# A64 register map
Vendor: Allwinner; Series: A64; File version: 0.1
CPU: CA53 0, little endian, MPU, no FPU, 0 interrupt priority bits
Registers are 32-bit, read-write, reset 0x0 unless marked. A register's access mark holds for its fields unless they carry their own. Offsets are from the block's base; [hi:lo] are bit positions; 'fields as' and 'values as' point back to an identical list; <NAME> marks a mode.

## AC (part 2 of 2)
Base 0x01C22C00
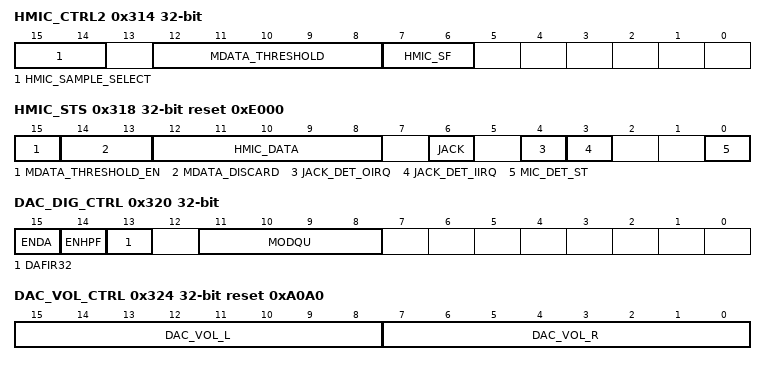
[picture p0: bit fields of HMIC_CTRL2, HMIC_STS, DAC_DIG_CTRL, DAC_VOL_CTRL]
0x314 HMIC_CTRL2 — HMIC Control 2 Register
  [15:14] HMIC_SAMPLE_SELECT — Down Sample Setting Select 00 : Down by 1, 128Hz 01 : Down by 2, 64Hz 10 : Down by 4, 32Hz 11 : Down by 8, 16Hz
  [12:8] MDATA_THRESHOLD — MIC DATA De-Bounce DATA
  [7:6] HMIC_SF — Hmic Smooth Filter setting 00: by pass 01: (x1+x2)/2 10: (x1+x2+x3+x4)/4 11: (x1+x2+x3+x4+x5+x6+x7+x8)/8
    0=by (by pass); 1=_openingparen_x1_plus_x2_closingparen__slash_2 ((x1+x2)/2); 2=_openingparen_x1_plus_x2_plus_x3_plus_x4_closingparen__slash_4 ((x1+x2+x3+x4)/4); 3=_openingparen_x1_plus_x2_plus_x3_plus_x4_plus_x5_plus_x6_plus_x7_plus_x8_closingparen__slash_8 ((x1+x2+x3+x4+x5+x6+x7+x8)/8)
0x318 HMIC_STS reset 0xE000 — HMIC Status Register
  [15] MDATA_THRESHOLD_EN — 0 : The MIC Threshold Data write by user 1 : The MIC Threshold Data is auto write
  [14:13] MDATA_DISCARD — After MIC DATA data receiving, the first N-data will be discarded. N defined as follows: 00 0; None discarded 01 1; 1-data discarded 10 2; 2-data discarded 11 4; 4-data discarded
  [12:8] HMIC_DATA ro — HMIC Average Data
  [6] JACK — Jack Detect Status 0:Not MIC/Accessory present 1:MIC/Accessory is present(impedance is < 30K ohm)
  [4] JACK_DET_OIRQ — Jack output detect pending interrupt 0: No Pending IRQ 1:Pending IRQ Writing 1 clear pending
    0=No Pending IRQ 1:Pending IRQ Writing 1 clear pending
  [3] JACK_DET_IIRQ — Jack input detect pending interrupt 0: No Pending IRQ 1: Pending IRQ Writing 1 clear pending
    0=No Pending IRQ; 1=Pending IRQ Writing 1 clear pending
  [0] MIC_DET_ST — MIC Detect Pending interrupt 0:No pending IRQ 1:Pending IRQ Writing 1 clear pending
0x320 DAC_DIG_CTRL — DAC Digital Control Register
  [15] ENDA — DAC Digital Part Enable 0: Disabe 1: Enable
    0=Disabe; 1=Enable
  [14] ENHPF — HPF Function Enable 0: Enable 1: Disable
    0=Enable; 1=Disable
  [13] DAFIR32 — Enable 32-tap FIR filter 0: 64-tap 1: 32-tap
    0=_64_minus_tap (64-tap); 1=_32_minus_tap (32-tap)
  [11:8] MODQU — Internal DAC Quantization Levels Levels=[7*(21+MODQU[3:0])]/128 Default levels=7*21/128=1.15
0x324 DAC_VOL_CTRL reset 0xA0A0 — DAC Volume Control Register
  [15:8] DAC_VOL_L — DAC left channel volume (-119.25dB To 71.25dB, 0.75dB/Step) 0x00: Mute 0x01: -119.25dB ......... 0x9F = -0.75dB 0xA0 = 0dB 0xA1 = 0.75dB ......... 0xFF = 71.25dB
    0=Mute; 1=_minus_119_point_25dB (-119.25dB ......... 0x9F = -0.75dB 0xA0 = 0dB 0xA1 = 0.75dB ......... 0xFF = 71.25dB)
  [7:0] DAC_VOL_R — DAC right channel volume (-119.25dB To 71.25dB, 0.75dB/Step) 0x00: Mute 0x01: -119.25dB ......... 0x9F = -0.75dB 0xA0 = 0dB 0xA1 = 0.75dB ......... 0xFF = 71.25dB
    values as DAC_VOL_L
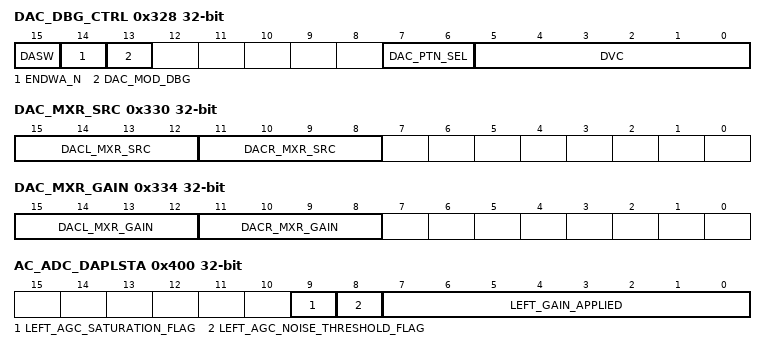
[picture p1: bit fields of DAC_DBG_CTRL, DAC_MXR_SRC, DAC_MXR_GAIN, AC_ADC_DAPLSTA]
0x328 DAC_DBG_CTRL — DAC Debug Control Register
  [15] DASW — DAC output channel swap enable 0:Disable 1:Enable
  [14] ENDWA_N — DWA Function Disable 0: Enable 1: Disable
    0=Enable; 1=Disable
  [13] DAC_MOD_DBG — DAC Modulator Debug 0: DAC Modulator Normal Mode 1: DAC Modulator Debug Mode
    0=DAC Modulator Normal Mode; 1=DAC Modulator Debug Mode
  [7:6] DAC_PTN_SEL — DAC Pattern Select 00: Normal(Audio sample from DAC mixer) 01: -6 dB sin wave 10: -60 dB sin wave 11: zero data
    0=Normal_openingparen_Audio_sample (Normal(Audio sample from DAC mixer)); 1=_minus_6_dB (-6 dB sin wave); 2=_minus_60_dB (-60 dB sin wave); 3=zero_data
  [5:0] DVC — Digital volume control, ATT=DVC[5:0]*(-1.16dB) 64 steps, -1.16dB/step
0x330 DAC_MXR_SRC — DAC Digital Mixer Source Select Register
  [15:12] DACL_MXR_SRC — DAC left channel mixer source select 0: Disable 1:Enable Bit15: AIF1 DAC0L Bit14: AIF1 DAC1L Bit13: AIF2 DACL Bit12: ADCL
  [11:8] DACR_MXR_SRC — DAC right channel mixer source select 0: Disable 1:Enable Bit11: AIF1 DAC0R Bit10: AIF1 DAC1R Bit9: AIF2 DACR Bit8: ADCR
0x334 DAC_MXR_GAIN — DAC Digital Mixer Gain Control Register
  [15:12] DACL_MXR_GAIN — DAC left channel mixer gain control 0: 0dB 1: -6dB Bit15: AIF1 DAC0L Bit14: AIF1 DAC1L Bit13: AIF2 DACL Bit12: ADCL
  [11:8] DACR_MXR_GAIN — DAC right channel mixer gain control 0: 0dB 1: -6dB Bit11: AIF1 DAC0R Bit10: AIF1 DAC1R Bit9: AIF2 DACR Bit8: ADCR
0x400 AC_ADC_DAPLSTA — ADC DAP Left Status Register
  [9] LEFT_AGC_SATURATION_FLAG ro
  [8] LEFT_AGC_NOISE_THRESHOLD_FLAG ro
  [7:0] LEFT_GAIN_APPLIED ro — Left Gain applied by AGC (7.1 format 2s complement(-20dB - 40dB), 0.5B/ step) 0x50: 40dB 0x4F: 39.5dB --------------- 0x00: 00dB 0xFF: -0.5dB
    80=_40dB; 79=_39_point_5dB (39.5dB ---------------); 0=_00dB; 255=_minus_0_point_5dB (-0.5dB)
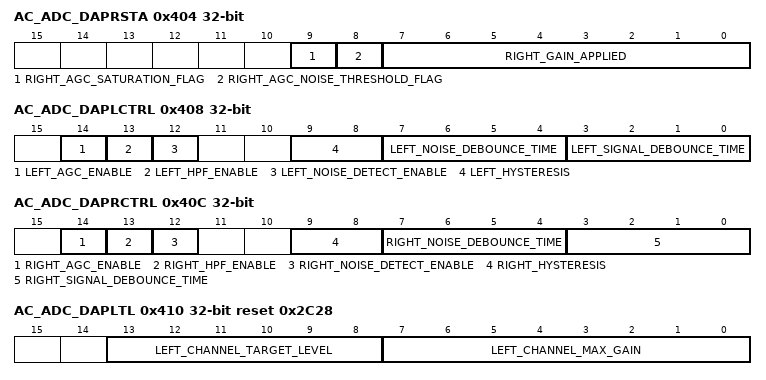
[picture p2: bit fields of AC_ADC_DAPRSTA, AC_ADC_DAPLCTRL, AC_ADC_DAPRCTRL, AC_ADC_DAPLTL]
0x404 AC_ADC_DAPRSTA — ADC DAP Right Status Register
  [9] RIGHT_AGC_SATURATION_FLAG ro
  [8] RIGHT_AGC_NOISE_THRESHOLD_FLAG ro
  [7:0] RIGHT_GAIN_APPLIED ro — Right Gain applied by AGC (7.1 format 2s complement(-20dB - 40dB), 0.5dB /step) 0x50: 40dB 0x4F: 39.5dB --------------- 0x00: 00dB 0xFF: -0.5dB
    values as AC_ADC_DAPLSTA.LEFT_GAIN_APPLIED
0x408 AC_ADC_DAPLCTRL — ADC DAP Left Channel Control Register
  [14] LEFT_AGC_ENABLE — Left AGC enable 0: disable 1: enable
    0=disable; 1=enable
  [13] LEFT_HPF_ENABLE — Left HPF enable 0: disable 1: enable
    0=disable; 1=enable
  [12] LEFT_NOISE_DETECT_ENABLE — Left Noise detect enable 0: disable 1: enable
    0=disable; 1=enable
  [9:8] LEFT_HYSTERESIS — Left Hysteresis setting 00: 1dB 01: 2dB 10: 4dB 11: disable;
    0=_1dB; 1=_2dB; 2=_4dB; 3=disable
  [7:4] LEFT_NOISE_DEBOUNCE_TIME — Left Noise debounce time 0000: disable 0001: 4/fs 0010: 8/fs ------------ 1111: 16*4096/fs T=2 /fs, except N=0
    0=disable; 1=_4_slash_fs (4/fs); 2=_8_slash_fs (8/fs ------------); 15=_16_times_4096_slash_fs (16*4096/fs T=2 /fs, except N=0)
  [3:0] LEFT_SIGNAL_DEBOUNCE_TIME — Left Signal debounce time 0000: disable 0001: 4/fs 0010: 8/fs ------------ 1111: 16*4096/fs T=2 /fs, except N=0
    values as LEFT_NOISE_DEBOUNCE_TIME
0x40C AC_ADC_DAPRCTRL — ADC DAP Right Channel Control Register
  [14] RIGHT_AGC_ENABLE — Right AGC enable 0: disable 1: enable
    0=disable; 1=enable
  [13] RIGHT_HPF_ENABLE — Right HPF enable 0: disable 1: enable
    0=disable; 1=enable
  [12] RIGHT_NOISE_DETECT_ENABLE — Right Noise detect enable 0: disable 1: enable
    0=disable; 1=enable
  [9:8] RIGHT_HYSTERESIS — Right Hysteresis setting 00: 1dB 01: 2dB 10: 4dB 11: disable
    0=_1dB; 1=_2dB; 2=_4dB; 3=disable
  [7:4] RIGHT_NOISE_DEBOUNCE_TIME — Right Noise debounce time 0000: disable 0001: 4/fs 0010: 8/fs ------------ 1111: 16*4096/fs T=2 /fs ,except N=0
    0=disable; 1=_4_slash_fs (4/fs); 2=_8_slash_fs (8/fs ------------); 15=_16_times_4096_slash_fs (16*4096/fs T=2 /fs ,except N=0)
  [3:0] RIGHT_SIGNAL_DEBOUNCE_TIME — Right Signal debounce time 0000: disable 0001: 4/fs 0010: 8/fs ------------ 1111: 16*4096/fs T=2 /fs, except N=0
    values as AC_ADC_DAPLCTRL.LEFT_NOISE_DEBOUNCE_TIME
0x410 AC_ADC_DAPLTL reset 0x2C28 — ADC DAP Left Target Level Register
  [13:8] LEFT_CHANNEL_TARGET_LEVEL — Left channel target level setting(-1dB -- -30dB).(6.0format 2s complement)
  [7:0] LEFT_CHANNEL_MAX_GAIN — Left channel max gain setting(0-40dB).(7.1format 2s complement)
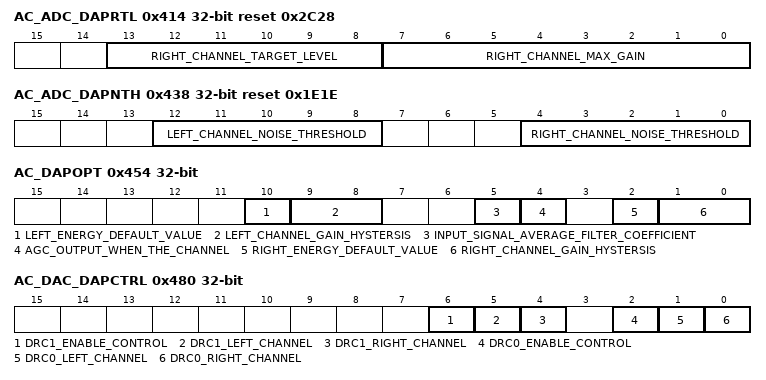
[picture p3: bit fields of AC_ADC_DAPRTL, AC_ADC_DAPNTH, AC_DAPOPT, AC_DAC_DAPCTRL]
0x414 AC_ADC_DAPRTL reset 0x2C28 — ADC DAP Right Target Level Register
  [13:8] RIGHT_CHANNEL_TARGET_LEVEL — Right channel target level setting(-1dB -- -30dB).(6.0format 2s complement)
  [7:0] RIGHT_CHANNEL_MAX_GAIN — Right channel max gain setting (0-40dB). (7.1format 2s complement)
0x418 AC_ADC_DAPLHAC reset 0x5 — ADC DAP Left High Average Coef Register
  [10:0] LEFT_CHANNEL — Left channel output signal average level coefficient setting(the coefficient [reg06[10:0],reg07] is 3.24 format 2s complement)
0x41C AC_ADC_DAPLLAC reset 0x1EB8 — ADC DAP Left Low Average Coef Register
  [15:0] LEFT_CHANNEL — Left channel output signal average level coefficient setting(the coefficient [reg07[10:0],reg08] is 3.24 format 2s complement)
0x420 AC_ADC_DAPRHAC reset 0x5 — ADC DAP Right High Average Coef Register
  [10:0] RIGHT_CHANNEL — Right channel output signal average level coefficient setting(the coefficient [reg08[10:0],reg09] is 3.24 format 2s complement)
0x424 AC_ADC_DAPRLAC reset 0x1EB8 — ADC DAP Right Low Average Coef Register
  [15:0] RIGHT_CHANNEL — Right channel output signal average level coefficient setting(the coefficient [reg08[10:0],reg09] is 3.24 format 2s complement)
0x428 AC_ADC_DAPLDT reset 0x1F — ADC DAP Left Decay Time Register
  [14:0] LEFT_DECAY_TIME_COEFFICIENT — (32x32fs) Left decay time coefficient setting 0000: 1x32/fs 0001: 2x32/fs ------------------------ 7FFF: 2 x32/fs T=(n+1)*32/fs When the gain increases, the actual gain will increase 0.5dB at every decay time.
0x42C AC_ADC_DAPLAT — ADC DAP Left Attack Time Register
  [14:0] LEFT_ATTACK_TIME_COEFFICIENT — Left attack time coefficient setting 0000: 1x32/fs 0001: 2x32/fs ------------------------ 7FFF: 2 x32/fs T=(n+1)*32/fs When the gain decreases, the actual gain will decrease 0.5dB at every attack time.
0x430 AC_ADC_DAPRDT reset 0x1F — ADC DAP Right Decay Time Register
  [14:0] RIGHT_DECAY_TIME_COEFFICIENT — (32x32fs) Right decay time coefficient setting 0000: 1x32/fs 0001: 2x32/fs ------------------------ 7FFF: 2 x32/fs T=(n+1)*32/fs When the gain increases, the actual gain will increase 0.5dB at every decay time.
0x434 AC_ADC_DAPRAT — ADC DAP Right Attack Time Register
  [14:0] RIGHT_ATTACK_TIME_COEFFICIENT — Right attack time coefficient setting 0000: 1x32/fs 0001: 2x32/fs ------------------------ 7FFF: 2 x32/fs T=(n+1)*32/fs When the gain decreases, the actual gain will decrease 0.5dB at every attack time.
0x438 AC_ADC_DAPNTH reset 0x1E1E — ADC DAP Noise Threshold Register
  [12:8] LEFT_CHANNEL_NOISE_THRESHOLD — Left channel noise threshold setting. 0x00: -30dB 0x01: -32dB 0x02: -34dB -------------------------------------------- 0x1D: -88dB 0x1E: -90dB 0x1F: -90dB(the same as 0x1E)
    0=_minus_30dB (-30dB); 1=_minus_32dB (-32dB); 2=_minus_34dB (-34dB --------------------------------------------); 29=_minus_88dB (-88dB); 30=_minus_90dB (-90dB); 31=_minus_90dB_openingparen_the (-90dB(the same as 0x1E))
  [4:0] RIGHT_CHANNEL_NOISE_THRESHOLD — Right channel noise threshold setting(-90 -- -30dB). 0x00: -30dB 0x01: -32dB 0x02: -34dB -------------------------------------------- 0x1D: -88dB 0x1E: -90dB 0x1F: -90dB(the same as 0x1E)
    values as LEFT_CHANNEL_NOISE_THRESHOLD
0x43C AC_ADC_DAPLHNAC reset 0x5 — ADC DAP Left Input Signal High Average Coef Register
  [10:0] LEFT — Left input signal average filter coefficient to check noise or not(the coefficient [reg0f[10:0],reg10] is 3.24 format 2s complement), always the same as the left output signal average filter's.
0x440 AC_ADC_DAPLLNAC reset 0x1EB8 — ADC DAP Left Input Signal Low Average Coef Register
  [15:0] LEFT — Left input signal average filter coefficient to check noise or not(the coefficient [reg0f[10:0],reg10] is 3.24 format 2s complement) always the same as the left output signal average filter's
0x444 AC_ADC_DAPRHNAC reset 0x5 — ADC DAP Right Input Signal High Average Coef Register
  [10:0] RIGHT — Right input signal average filter coefficient to check noise or not(the coefficient [reg11[10:0],reg12] is 3.24 format 2s complement), always the same as the right output signal average filter's
0x448 AC_ADC_DAPRLNAC reset 0x1EB8 — ADC DAP Right Input Signal Low Average Coef Register
  [15:0] RIGHT — Right input signal average filter coefficient to check noise or not(the coefficient [reg11[10:0],reg12] is 3.24 format 2s complement), always the same as the right output signal average filter's
0x44C AC_DAPHHPFC reset 0xFF — ADC DAP High HPF Coef Register
  [10:0] HPF — coefficient setting(the coefficient [reg13[10:0],reg14] is 3.24 format 2s complement)
0x450 AC_DAPLHPFC reset 0xFAC1 — ADC DAP Low HPF Coef Register
  [15:0] HPF — coefficient setting(the coefficient [reg13[10:0],reg14] is 3.24 format 2s complement)
0x454 AC_DAPOPT — ADC DAP Optimum Register
  [10] LEFT_ENERGY_DEFAULT_VALUE — Left energy default value setting (include the input and output) 0: min 1: max
    0=min; 1=max
  [9:8] LEFT_CHANNEL_GAIN_HYSTERSIS — Left channel gain hystersis setting. The different between target level and the signal level must larger than the hystersis when the gain change. 00: 0.4375db 01: 0.9375db 10: 1.9375db 11: 3db
    0=_0_point_4375db (0.4375db); 1=_0_point_9375db (0.9375db); 2=_1_point_9375db (1.9375db); 3=_3db
  [5] INPUT_SIGNAL_AVERAGE_FILTER_COEFFICIENT — The input signal average filter coefficient setting 0: is the [reg0f[10:0], reg10] and [reg11[1:0], reg12]; 1: is the [reg06[10:0], reg07] and [reg08[1:0], reg09];
    0=is_the_[reg0f[10_colon_0] (is the [reg0f[10:0], reg10] and [reg11[1:0], reg12];); 1=is_the_[reg06[10_colon_0] (is the [reg06[10:0], reg07] and [reg08[1:0], reg09];)
  [4] AGC_OUTPUT_WHEN_THE_CHANNEL — AGC output when the channel in noise state 0: output is zero 1: output is the input data
    0=zero (output is zero); 1=the_input (output is the input data)
  [2] RIGHT_ENERGY_DEFAULT_VALUE — Right energy default value setting (include the input and output) 0: min 1: max
    0=min; 1=max
  [1:0] RIGHT_CHANNEL_GAIN_HYSTERSIS — Right channel gain hystersis setting. The different between target level and the signal level must larger than the hystersis when the gain change. 00: 0.4375db 01: 0.9375db 10: 1.9375db 11: 3db
    values as LEFT_CHANNEL_GAIN_HYSTERSIS
0x480 AC_DAC_DAPCTRL — DAC DAP Control Register
  [all] fields
    0=disable; 1=enable
  [6] DRC1_ENABLE_CONTROL — DRC1 enable control 0: disable 1: enable
  [5] DRC1_LEFT_CHANNEL — DRC1 Left channel HPF enable control 0: disable 1: enable
  [4] DRC1_RIGHT_CHANNEL — DRC1 Right channel HPF enable control 0: disable 1: enable
  [2] DRC0_ENABLE_CONTROL — DRC0 enable control 0: disable 1: enable
  [1] DRC0_LEFT_CHANNEL — DRC0 Left channel HPF enable control 0: disable 1: enable
  [0] DRC0_RIGHT_CHANNEL — DRC0 Right channel HPF enable control 0: disable 1: enable
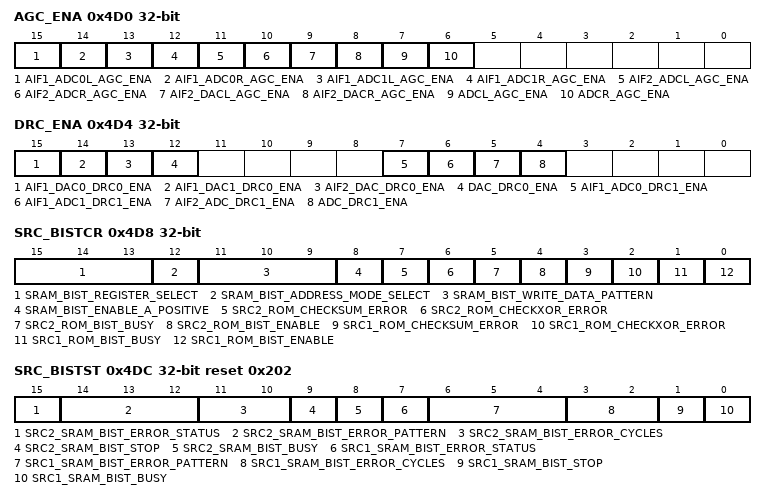
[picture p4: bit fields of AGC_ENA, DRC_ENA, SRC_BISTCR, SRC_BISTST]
0x4D0 AGC_ENA — AGC Enable Register
  [all] fields
    0=Disable; 1=Enable
  [15] AIF1_ADC0L_AGC_ENA — AIF1 ADC timeslot 0 left channel AGC enable 0: Disable 1: Enable
  [14] AIF1_ADC0R_AGC_ENA — AIF1 ADC timeslot 0 right channel AGC enable 0: Disable 1: Enable
  [13] AIF1_ADC1L_AGC_ENA — AIF1 ADC timeslot 1 left channel AGC enable 0: Disable 1: Enable
  [12] AIF1_ADC1R_AGC_ENA — AIF1 ADC timeslot 1 right channel AGC enable 0: Disable 1: Enable
  [11] AIF2_ADCL_AGC_ENA — AIF2 ADC left channel AGC enable 0: Disable 1: Enable
  [10] AIF2_ADCR_AGC_ENA — AIF2 ADC right channel AGC enable 0: Disable 1: Enable
  [9] AIF2_DACL_AGC_ENA — AIF2 DAC left channel AGC enable 0: Disable 1: Enable
  [8] AIF2_DACR_AGC_ENA — AIF2 DAC right channel AGC enable 0: Disable 1: Enable
  [7] ADCL_AGC_ENA — ADC left channel AGC enable 0: Disable 1: Enable
  [6] ADCR_AGC_ENA — ADC right channel AGC enable 0: Disable 1: Enable
0x4D4 DRC_ENA — DRC Enable Register
  [15] AIF1_DAC0_DRC0_ENA — AIF1 DAC timeslot 0 DRC0 enable 0: Disable 1: Enable
    0=Disable; 1=Enable
  [14] AIF1_DAC1_DRC0_ENA — AIF1 DAC timeslot 1 DRC0 enable 0: Disable 1: Enable
    0=Disable; 1=Enable
  [13] AIF2_DAC_DRC0_ENA — AIF2 DAC DRC0 enable 0: Disable 1: Enable
    0=Disable; 1=Enable
  [12] DAC_DRC0_ENA — DAC DRC0 enable 0: Disable 1: Enable
    0=Disable; 1=Enable
  [7] AIF1_ADC0_DRC1_ENA — AIF1 ADC timeslot 0 DRC1 enable 0 : Disable 1 : Enable
  [6] AIF1_ADC1_DRC1_ENA — AIF1 ADC timeslot 1 DRC1 enable 0 : Disable 1 : Enable
  [5] AIF2_ADC_DRC1_ENA — AIF2 ADC DRC1 enable 0 : Disable 1 : Enable
  [4] ADC_DRC1_ENA — ADC_DRC1 enable 0 : Disable 1 : Enable
0x4D8 SRC_BISTCR — SRC Bist control Register
  [15:13] SRAM_BIST_REGISTER_SELECT
  [12] SRAM_BIST_ADDRESS_MODE_SELECT
  [11:9] SRAM_BIST_WRITE_DATA_PATTERN — SRAM BIST Write Data Pattern 0: 0x0000_0000 1: 0x5555_5555 2: 0x3333_3333 3: 0x0f0f_0f0f 4: 0x00ff_00ff 5: 0x0000_ffff Others, reserved.
    2=_0x3333_3333; 3=_0x0f0f_0f0f; 4=_0x00ff_00ff; 5=0x0000_ffff Others, reserved
  [8] SRAM_BIST_ENABLE_A_POSITIVE — SRAM BIST Enable A positive edge will trigger the SRAM BIST to start
  [7] SRC2_ROM_CHECKSUM_ERROR ro — SRC2 ROM CheckSum Error 0: No Error 1: Error
    0=No_Error; 1=Error
  [6] SRC2_ROM_CHECKXOR_ERROR ro — SRC2 ROM CheckXor Error 0: No Error 1: Error
    0=No_Error; 1=Error
  [5] SRC2_ROM_BIST_BUSY ro — SRC2 ROM BIST Busy 0: Idle 1: Busy
    0=Idle; 1=Busy
  [4] SRC2_ROM_BIST_ENABLE — SRC2 ROM BIST Enable A positive edge will trigger the ROM BIST to start
  [3] SRC1_ROM_CHECKSUM_ERROR ro — SRC1 ROM CheckSum Error 0: No Error 1: Error
    0=No_Error; 1=Error
  [2] SRC1_ROM_CHECKXOR_ERROR ro — SRC1 ROM CheckXor Error 0: No Error 1: Error
    0=No_Error; 1=Error
  [1] SRC1_ROM_BIST_BUSY ro — SRC1 ROM BIST Busy 0: Idle 1: Busy
    0=Idle; 1=Busy
  [0] SRC1_ROM_BIST_ENABLE — SRC1 ROM BIST Enable A positive edge will trigger the ROM BIST to start
0x4DC SRC_BISTST reset 0x202 — SRC Bist Status Register
  [15] SRC2_SRAM_BIST_ERROR_STATUS ro — SRC2 SRAM BIST Error Status 0: No Error 1: Error
    0=No_Error; 1=Error
  [14:12] SRC2_SRAM_BIST_ERROR_PATTERN ro
  [11:10] SRC2_SRAM_BIST_ERROR_CYCLES ro
  [9] SRC2_SRAM_BIST_STOP ro — SRC2 SRAM BIST Stop 0: Running 1: Stop
    0=Running; 1=Stop
  [8] SRC2_SRAM_BIST_BUSY ro — SRC2 SRAM BIST Busy 0: Idle 1: Busy
    0=Idle; 1=Busy
  [7] SRC1_SRAM_BIST_ERROR_STATUS ro — SRC1 SRAM BIST Error Status 0: No Error 1: Error
    0=No_Error; 1=Error
  [6:4] SRC1_SRAM_BIST_ERROR_PATTERN ro
  [3:2] SRC1_SRAM_BIST_ERROR_CYCLES ro
  [1] SRC1_SRAM_BIST_STOP ro — SRC1 SRAM BIST Stop 0: Running 1: Stop
    0=Running; 1=Stop
  [0] SRC1_SRAM_BIST_BUSY ro — SRC1 SRAM BIST Busy 0: Idle 1: Busy
    0=Idle; 1=Busy
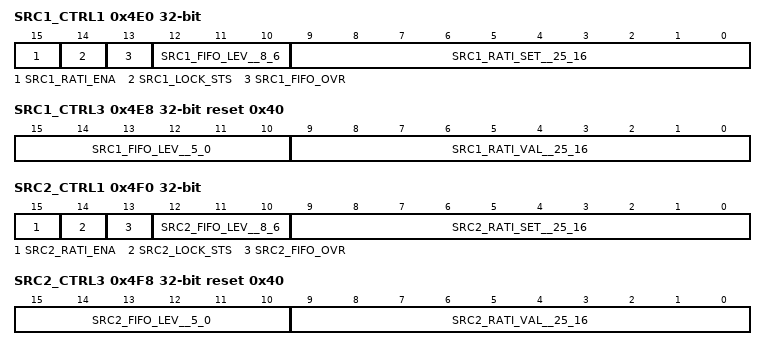
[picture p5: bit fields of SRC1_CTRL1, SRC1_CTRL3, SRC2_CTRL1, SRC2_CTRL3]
0x4E0 SRC1_CTRL1 — SRC1 Control 1 Register
  [15] SRC1_RATI_ENA — SRC1 Manual setting ratio enable 0-disable 1-enable
  [14] SRC1_LOCK_STS ro — SRC1 Ratio lock status 0-not locked 1-locked
  [13] SRC1_FIFO_OVR ro — SRC1 FIFO Overflow status 0-normal 1-overflowed
  [12:10] SRC1_FIFO_LEV__8_6 ro — SRC1_FIFO_LEV_[8:6] SRC1 FIFO Level high 3-bit
  [9:0] SRC1_RATI_SET__25_16 — SRC1_RATI_SET_[25:16] Manual setting ratio high 10-bit
0x4E4 SRC1_CTRL2 — SRC1 Control 2 Register
  [15:0] SRC1_RATI_SET__15_0 — SRC1_RATI_SET_[15:0] Manual setting ratio low 16-bit
0x4E8 SRC1_CTRL3 reset 0x40 — SRC1 Control 3 Register
  [15:10] SRC1_FIFO_LEV__5_0 ro — SRC1_FIFO_LEV_[5:0] SRC1 FIFO Level low 6-bit
  [9:0] SRC1_RATI_VAL__25_16 ro — SRC1_RATI_VAL_[25:16] Calculated ratio high 10-bit
0x4EC SRC1_CTRL4 — SRC1 Control 4 Register
  [15:0] SRC1_RATI_VAL__15_0 ro — SRC1_RATI_VAL_[15:0] Calculated ratio low 16-bit
0x4F0 SRC2_CTRL1 — SRC2 Control 1 Register
  [15] SRC2_RATI_ENA — SRC2 Manual setting ratio enable 0-disable 1-enable
  [14] SRC2_LOCK_STS ro — SRC2 Ratio lock status 0-not locked 1-locked
  [13] SRC2_FIFO_OVR ro — SRC2 FIFO Overflow status 0-normal 1-overflowed
  [12:10] SRC2_FIFO_LEV__8_6 ro — SRC2_FIFO_LEV_[8:6] SRC2 FIFO Level high 3-bit
  [9:0] SRC2_RATI_SET__25_16 — SRC2_RATI_SET_[25:16] Manual setting ratio high 10-bit
0x4F4 SRC2_CTRL2 — SRC2 Control 2 Register
  [15:0] SRC2_RATI_SET__15_0 — SRC2_RATI_SET_[15:0] Manual setting ratio low 16-bit
0x4F8 SRC2_CTRL3 reset 0x40 — SRC2 Control 3 Register
  [15:10] SRC2_FIFO_LEV__5_0 ro — SRC2_FIFO_LEV_[5:0] SRC2 FIFO Level low 6-bit
  [9:0] SRC2_RATI_VAL__25_16 ro — SRC2_RATI_VAL_[25:16] Calculated ratio high 10-bit
0x4FC SRC2_CTRL4 — SRC2 Control 4 Register
  [15:0] SRC2_RATI_VAL__15_0 ro — SRC2_RATI_VAL_[15:0] Calculated ratio low 16-bit
0x600 AC_DRC0_HHPFC reset 0xFF — DRC0 High HPF Coef Register
  [10:0] HPF — coefficient setting and the data is 3.24 format.
0x604 AC_DRC0_LHPFC reset 0xFAC1 — DRC0 Low HPF Coef Register
  [15:0] HPF — coefficient setting and the data is 3.24 format.
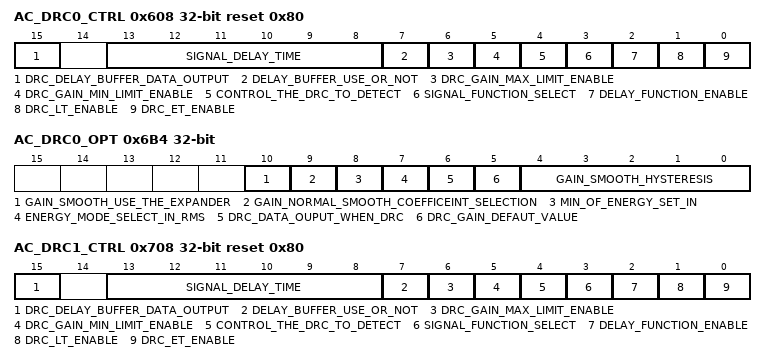
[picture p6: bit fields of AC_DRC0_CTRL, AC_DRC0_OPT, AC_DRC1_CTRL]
0x608 AC_DRC0_CTRL reset 0x80 — DRC0 Control Register
  [15] DRC_DELAY_BUFFER_DATA_OUTPUT ro — DRC delay buffer data output state when drc delay function is enble and the drc funciton disable. After disable drc function and this bit go to 0, the user should write the drc delay function bit to 0; 0 : not complete 1 : is complete
  [13:8] SIGNAL_DELAY_TIME — Signal delay time setting 6'h00 : (8x1)fs 6'h01 : (8x2)fs 6'h02 : (8x3)fs ---------------------------------------- 6'h2e : (8*47)fs 6'h2f : (8*48)fs 6'h30 -- 6'h3f : (8*48)fs Delay time = 8*(n+1)fs, n<6'h30; When the delay function is disable, the signal delay time is unused.
  [7] DELAY_BUFFER_USE_OR_NOT — The delay buffer use or not when the drc disable and the drc buffer data output completely 0 : don't use the buffer 1 : use the buffer
  [6] DRC_GAIN_MAX_LIMIT_ENABLE — DRC gain max limit enable 0 : disable 1 : enable
  [5] DRC_GAIN_MIN_LIMIT_ENABLE — DRC gain min limit enable. when this fuction enable, it will overwrite the noise detect funciton. 0 : disable 1 : enable
  [4] CONTROL_THE_DRC_TO_DETECT — Control the drc to detect noise when ET enable 0 : disable 1 : enable
  [3] SIGNAL_FUNCTION_SELECT — Signal function Select 0 : RMS filter 1 : Peak filter When Signal function Select Peak filter, the RMS parameter is unused. (AC_DRC_LRMSHAT / AC_DRC_LRMSLAT / AC_DRC_LRMSHAT / AC_DRC_LRMSLAT) When Signal function Select RMS filter, the Peak filter parameter is unused.(AC_DRC_LPFHAT / AC_DRC_LPFLAT / AC_DRC_RPFHAT / AC_DRC_RPFLAT / AC_DRC_LPFHRT / AC_DRC_LPFLRT / AC_DRC_RPFHRT / AC_DRC_RPFLRT)
  [2] DELAY_FUNCTION_ENABLE — Delay function enable 0 : disable 1 : enable When the Delay function enable is disable, the Signal delay time is unused.
  [1] DRC_LT_ENABLE — DRC LT enable 0 : disable 1 : enable When the DRC LT is disable the LT, Kl and OPL parameter is unused.
  [0] DRC_ET_ENABLE — DRC ET enable 0 : disable 1 : enable When the DRC ET is disable the ET, Ke and OPE parameter is unused.
0x60C AC_DRC0_LPFHAT reset 0xB — DRC0 Left Peak Filter High Attack Time Coef Register
  [10:0] LEFT_PEAK_FILTER_ATTACK_TIME — The left peak filter attack time parameter setting, which determine by the equation that AT = 1-exp(-2.2Ts/ta). The format is 3.24. (1ms)
0x610 AC_DRC0_LPFLAT reset 0x77BF — DRC0 Left Peak Filter Low Attack Time Coef Register
  [15:0] LEFT_PEAK_FILTER_ATTACK_TIME — The left peak filter attack time parameter setting, which determine by the equation that AT = 1-exp(-2.2Ts/ta). The format is 3.24. (1ms)
0x614 AC_DRC0_RPFHAT reset 0xB — DRC0 Right Peak Filter High Attack Time Coef Register
  fields as AC_DRC0_LPFHAT
0x618 AC_DRC0_RPFLAT reset 0x77BF — DRC0 Peak Filter Low Attack Time Coef Register
  fields as AC_DRC0_LPFLAT
0x61C AC_DRC0_LPFHRT reset 0xFF — DRC0 Left Peak Filter High Release Time Coef Register
  [10:0] LEFT_PEAK_FILTER_RELEASE_TIME — The left peak filter release time parameter setting, which determine by the equation that RT = exp(-2.2Ts/tr). The format is 3.24. (100ms)
0x620 AC_DRC0_LPFLRT reset 0xE1F8 — DRC0 Left Peak Filter Low Release Time Coef Register
  [15:0] LEFT_PEAK_FILTER_RELEASE_TIME — The left peak filter release time parameter setting, which determine by the equation that RT = exp(-2.2Ts/tr). The format is 3.24. (100ms)
0x624 AC_DRC0_RPFHRT reset 0xFF — DRC0 Right Peak filter High Release Time Coef Register
  [10:0] LEFT_PEAK_FILTER_ATTACK_TIME — The left peak filter attack time parameter setting, which determine by the equation that RT = exp(-2.2Ts/tr). The format is 3.24. (100ms)
0x628 AC_DRC0_RPFLRT reset 0xE1F8 — DRC0 Right Peak filter Low Release Time Coef Register
  [15:0] LEFT_PEAK_FILTER_RELEASE_TIME — The left peak filter release time parameter setting, which determine by the equation that AT = exp(-2.2Ts/tr). The format is 3.24. (100ms)
0x62C AC_DRC0_LRMSHAT reset 0x1 — DRC0 Left RMS Filter High Coef Register
  [10:0] LEFT_RMS_FILTER_AVERAGE_TIME — The left RMS filter average time parameter setting, which determine by the equation that AT = 1-exp(-2.2Ts/tav). The format is 3.24. (10ms)
0x630 AC_DRC0_LRMSLAT reset 0x2BAF — DRC0 Left RMS Filter Low Coef Register
  [15:0] LEFT_RMS_FILTER_AVERAGE_TIME — The left RMS filter average time parameter setting, which determine by the equation that AT = 1-exp(-2.2Ts/tav). The format is 3.24. (10ms)
0x634 AC_DRC0_RRMSHAT reset 0x1 — DRC0 Right RMS Filter High Coef Register
  [10:0] RIGHT_RMS_FILTER_AVERAGE_TIME — The right RMS filter average time parameter setting, which determine by the equation that AT = 1-exp(-2.2Ts/tav). The format is 3.24. (10ms)
0x638 AC_DRC0_RRMSLAT reset 0x2BAF — DRC0 Right RMS Filter Low Coef Register
  [15:0] RIGHT_RMS_FILTER_AVERAGE_TIME — The right RMS filter average time parameter setting, which determine by the equation that AT = 1-exp(-2.2Ts/tav). The format is 3.24. (10ms)
0x63C AC_DRC0_HCT reset 0x6A4 — DRC0 Compressor Theshold High Setting Register
  [15:0] COMPRESSOR_THRESHOLD — The compressor threshold setting, which set by the equation that CTin = -CT/6.0206. The format is 8.24 (-40dB)
0x640 AC_DRC0_LCT reset 0xD3C0 — DRC0 Compressor Slope High Setting Register
  fields as AC_DRC0_HCT
0x644 AC_DRC0_HKC reset 0x80 — DRC0 Compressor Slope High Setting Register
  [13:0] COMPRESSOR_SLOPE — The slope of the compressor which determine by the equation that Kc = 1/R, there, R is the ratio of the compressor, which always is interger. The format is 8.24. (2 : 1)
0x648 AC_DRC0_LKC — DRC0 Compressor Slope Low Setting Register
  [15:0] COMPRESSOR_SLOPE — The slope of the compressor which determine by the equation that Kc = 1/R, there, R is the ratio of the compressor, which always is interger. The format is 8.24. (2 : 1)
0x64C AC_DRC0_HOPC reset 0xF95B — DRC0 Compressor High Output at Compressor Threshold Register
  [15:0] COMPRESSOR_OUTPUT — The output of the compressor which determine by the equation -OPC/6.0206 The format is 8.24 (-40dB)
0x650 AC_DRC0_LOPC reset 0x2C3F — DRC0 Compressor Low Output at Compressor Threshold Register
  [15:0] COMPRESSOR_OUTPUT — The output of the compressor which determine by the equation OPC/6.0206 The format is 8.24 (-40dB)
0x654 AC_DRC0_HLT reset 0x1A9 — DRC0 Limiter Theshold High Setting Register
  [15:0] LIMITER_THRESHOLD — The limiter threshold setting, which set by the equation that LTin = -LT/6.0206, The format is 8.24. (-10dB)
0x658 AC_DRC0_LLT reset 0x34F0 — DRC0 Limiter Theshold Low Setting Register
  fields as AC_DRC0_HLT
0x65C AC_DRC0_HK1 reset 0x5
  [13:0] LIMITER_SLOPE — The slope of the limiter which determine by the equation that Kl = 1/R, there, R is the ratio of the limiter, which always is interger. The format is 8.24. (50 :1)
0x660 AC_DRC0_LK1 reset 0x1EB8
  [15:0] LIMITER_SLOPE — The slope of the limiter which determine by the equation that Kl = 1/R, there, R is the ratio of the limiter, which always is interger. The format is 8.24. (50 :1)
0x664 AC_DRC0_HOPL reset 0xFBD8 — DRC0 Limiter High Output at Limiter Threshold
  [15:0] LIMITER_OUTPUT — The output of the limiter which determine by equation OPT/6.0206. The format is 8.24 (-25dB)
0x668 AC_DRC0_LOPL reset 0xFBA7 — DRC0 Limiter Low Output at Limiter Threshold
  fields as AC_DRC0_HOPL
0x66C AC_DRC0_HET reset 0xBA0 — DRC0 Expander Theshold High Setting Register
  [15:0] EXPANDER_THRESHOLD — The expander threshold setting, which set by the equation that ETin = -ET/6.0206, The format is 8.24. (-70dB)
0x670 AC_DRC0_LET reset 0x7291 — DRC0 Expander Theshold Low Setting Register
  fields as AC_DRC0_HET
0x674 AC_DRC0_HKE reset 0x50 — DRC0 Expander Slope High Setting Register
  [13:0] EXPANDER_SLOPE — The slope of the expander which determine by the equation that Ke = 1/R, there, R is the ratio of the expander, which always is interger and the ke must larger than 50. The format is 8.24. (1:5)
0x678 AC_DRC0_LKE — DRC0 Expander Slope Low Setting Register
  [15:0] EXPANDER_SLOPE — The slope of the expander which determine by the equation that Ke = 1/R, there, R is the ratio of the expander, which always is interger and the ke must larger than 50. The format is 8.24. (1:5)
0x67C AC_DRC0_HOPE reset 0xF45F — DRC0 Expander High Output at Expander Threshold
  [15:0] EXPANDER_OUTPUT — The output of the expander which determine by equation OPE/6.0206. The format is 8.24 (-70dB)
0x680 AC_DRC0_LOPE reset 0x8D6E — DRC0 Expander Low Output at Expander Threshold
  fields as AC_DRC0_HOPE
0x684 AC_DRC0_HKN reset 0x100 — DRC0 Linear Slope High Setting Register
  [13:0] LINEAR_SLOPE — The slope of the linear which determine by the equation that Kn = 1/R, there, R is the ratio of the linear, which always is interger . The format is 8.24. (1:1)
0x688 AC_DRC0_LKN — DRC0 Linear Slope Low Setting Register
  [15:0] LINEAR_SLOPE — The slope of the linear which determine by the equation that Kn = 1/R, there, R is the ratio of the linear, which always is interger . The format is 8.24. (1:1)
0x68C AC_DRC0_SFHAT reset 0x2 — DRC0 Smooth filter Gain High Attack Time Coef Register
  [10:0] SMOOTH_FILTER_ATTACK_TIME — The smooth filter attack time parameter setting, which determine by the equation that AT = 1-exp(-2.2Ts/tr). The format is 3.24. (5ms)
0x690 AC_DRC0_SFLAT reset 0x5600 — DRC0 Smooth filter Gain Low Attack Time Coef Register
  [15:0] SMOOTH_FILTER_ATTACK_TIME — The smooth filter attack time parameter setting, which determine by the equation that AT = 1-exp(-2.2Ts/tr). The format is 3.24. (5ms)
0x694 AC_DRC0_SFHRT — DRC0 Smooth filter Gain High Release Time Coef Register
  [10:0] GAIN_SMOOTH_FILTER_RELEASE_TIME — The gain smooth filter release time parameter setting, which determine by the equation that RT = 1-exp(-2.2Ts/tr). The format is 3.24. (200ms)
0x698 AC_DRC0_SFLRT reset 0xF04 — DRC0 Smooth filter Gain Low Release Time Coef Register
  [15:0] GAIN_SMOOTH_FILTER_RELEASE_TIME — The gain smooth filter release time parameter setting, which determine by the equation that RT = 1-exp(-2.2Ts/tr). The format is 3.24. (200ms)
0x69C AC_DRC0_MXGHS reset 0xFE56 — DRC0 MAX Gain High Setting Register
  [15:0] MAX_GAIN — The max gain setting which determine by equation MXG/6.0206. The format is 8.24 and must -20dB <MXG< 30dB (-10dB)
0x6A0 AC_DRC0_MXGLS reset 0xCB0F — DRC0 MAX Gain Low Setting Register
  [15:0] MAX_GAIN — The max gain setting which determine by equation MXG/6.0206. The format is 8.24 and must -20dB <MXG < 30dB (-10dB)
0x6A4 AC_DRC0_MNGHS reset 0xF95B — DRC0 MIN Gain High Setting Register
  [15:0] MIN_GAIN — The min gain setting which determine by equation MXG/6.0206. The format is 8.24 and must -60dB MNG -40dB (-40dB)
0x6A8 AC_DRC0_MNGLS reset 0x2C3F — DRC0 MIN Gain Low Setting Register
  [15:0] MIN_GAIN — The min gain setting which determine by equation MNG/6.0206. The format is 8.24 and must -60dB MNG -40dB (-40dB)
0x6AC AC_DRC0_EPSHC — DRC0 Expander Smooth Time High Coef Register
  [11:0] GAIN_SMOOTH_FILTER_RELEASE — The gain smooth filter release and attack time parameter setting in expander region, which determine by the equation that RT = 1-exp(-2.2Ts/tr). The format is 3.24. (30ms)
0x6B0 AC_DRC0_EPSLC reset 0x640C — DRC0 Expander Smooth Time Low Coef Register
  [15:0] GAIN_SMOOTH_FILTER_RELEASE — The gain smooth filter release and attack time parameter setting in expander region, which determine by the equation that RT = 1-exp(-2.2Ts/tr). The format is 3.24. (30ms)
0x6B4 AC_DRC0_OPT — DRC0 Optimum Register
  [10] GAIN_SMOOTH_USE_THE_EXPANDER — The gain smooth use the expander coiffcient when the energy in expander range 0 : use the normal smooth coeffcient 1 : use the expander coeffcient
  [9] GAIN_NORMAL_SMOOTH_COEFFICEINT_SELECTION — The gain normal smooth coefficeint selection mode set 0 : both release and attack coeffcient use hysteresis; 1 : only the attack coeffcient use hysteresis;
  [8] MIN_OF_ENERGY_SET_IN — The min of energy set in Peak detect mode 0 : -120dB 1 : -210dB
  [7] ENERGY_MODE_SELECT_IN_RMS — The energy mode select in rms detect mode 0 : the energy is RMS 1 : the energy is square of RMS
  [6] DRC_DATA_OUPUT_WHEN_DRC — DRC data ouput when DRC disable and DRC delay data output complete. 0 : the ouput is the input music data; 1 : the output is 0 ;
  [5] DRC_GAIN_DEFAUT_VALUE — DRC gain defaut value setting 0: The default gain is 1 1: The default gain is 0
    0=The default gain is 1; 1=The default gain is 0
  [4:0] GAIN_SMOOTH_HYSTERESIS — The hysteresis of the gain smooth filter to use the decay time coefficient or the attack time coefficient. When in the decay time state, if g(n-1)-g(n)>hysteresis, then the state will change to attack time state, and when in the attack time, if g(n)-g(n-1)>hysteresis, then the state will change to decay time state. Note the hysteresis of 0x00 and 0x04 is the same. 00000: 00001: 00010: 00011: 00100: ----------------- 10011: 10100 ~11111: 1 hysteresis = ,except n=0x00, and n less 0x14.
    0=0b00000; 1=0b00001; 2=0b00010; 3=0b00011; 4=_minus__minus__minus__minus__minus__minus__minus__minus__minus__minus__minus__minus__minus__minus__minus__minus__minus_; 19=10100 ~11111: 1 hysteresis = ,except n=0x00, and n less 0x14
0x6B8 AC_DRC0_HPFHGAIN reset 0x100
  [10:0] HPF_COEFFICIENT_GAIN — The gain of the hpf coefficient setting which format is 3.24.(gain = 1)
0x6BC AC_DRC0_HPFLGAIN
  [15:0] HPF_COEFFICIENT_GAIN — The gain of the hpf coefficient setting which format is 3.24.(gain = 1)
0x700 AC_DRC1_HHPFC reset 0xFF — DRC1 High HPF Coef Register
  [10:0] HPF — coefficient setting and the data is 3.24 format.
0x704 AC_DRC1_LHPFC reset 0xFAC1 — DRC1 Low HPF Coef Register
  [15:0] HPF — coefficient setting and the data is 3.24 format.
0x708 AC_DRC1_CTRL reset 0x80 — DRC1 Control Register
  fields as AC_DRC0_CTRL
0x70C AC_DRC1_LPFHAT reset 0xB — DRC1 Left Peak Filter High Attack Time Coef Register
  fields as AC_DRC0_LPFHAT
0x710 AC_DRC1_LPFLAT reset 0x77BF — DRC1 Left Peak Filter Low Attack Time Coef Register
  fields as AC_DRC0_LPFLAT
0x714 AC_DRC1_RPFHAT reset 0xB — DRC1 Right Peak Filter High Attack Time Coef Register
  fields as AC_DRC0_LPFHAT
0x718 AC_DRC1_RPFLAT reset 0x77BF — DRC1 Peak Filter Low Attack Time Coef Register
  fields as AC_DRC0_LPFLAT
0x71C AC_DRC1_LPFHRT reset 0xFF — DRC1 Left Peak Filter High Release Time Coef Register
  fields as AC_DRC0_LPFHRT
0x720 AC_DRC1_LPFLRT reset 0xE1F8 — DRC1 Left Peak Filter Low Release Time Coef Register
  fields as AC_DRC0_LPFLRT
0x724 AC_DRC1_RPFHRT reset 0xFF — DRC1 Right Peak filter High Release Time Coef Register
  fields as AC_DRC0_RPFHRT
0x728 AC_DRC1_RPFLRT reset 0xE1F8 — DRC1 Right Peak filter Low Release Time Coef Register
  fields as AC_DRC0_RPFLRT
0x72C AC_DRC1_LRMSHAT reset 0x1 — DRC1 Left RMS Filter High Coef Register
  fields as AC_DRC0_LRMSHAT
0x730 AC_DRC1_LRMSLAT reset 0x2BAF — DRC1 Left RMS Filter Low Coef Register
  fields as AC_DRC0_LRMSLAT
0x734 AC_DRC1_RRMSHAT reset 0x1 — DRC1 Right RMS Filter High Coef Register
  fields as AC_DRC0_RRMSHAT
0x738 AC_DRC1_RRMSLAT reset 0x2BAF — DRC1 Right RMS Filter Low Coef Register
  fields as AC_DRC0_RRMSLAT
0x73C AC_DRC1_HCT reset 0x6A4 — DRC1 Compressor Theshold High Setting Register
  fields as AC_DRC0_HCT
0x740 AC_DRC1_LCT reset 0xD3C0 — DRC1 Compressor Slope High Setting Register
  fields as AC_DRC0_HCT
0x744 AC_DRC1_HKC reset 0x800 — DRC1 Compressor Slope High Setting Register
  fields as AC_DRC0_HKC
0x748 AC_DRC1_LKC — DRC1 Compressor Slope Low Setting Register
  fields as AC_DRC0_LKC
0x74C AC_DRC1_HOPC reset 0xF95B — DRC1 Compressor High Output at Compressor Threshold Register
  fields as AC_DRC0_HOPC
0x750 AC_DRC1_LOPC reset 0x2C3F — DRC1 Compressor Low Output at Compressor Threshold Register
  fields as AC_DRC0_LOPC
0x754 AC_DRC1_HLT reset 0x1A9 — DRC1 Limiter Theshold High Setting Register
  fields as AC_DRC0_HLT
0x758 AC_DRC1_LLT reset 0x34F0 — DRC1 Limiter Theshold Low Setting Register
  fields as AC_DRC0_HLT
0x75C AC_DRC1_HK1 reset 0x5
  fields as AC_DRC0_HK1
0x760 AC_DRC1_LK1 reset 0x1EB8
  fields as AC_DRC0_LK1
0x764 AC_DRC1_HOPL reset 0xFBD8 — DRC1 Limiter High Output at Limiter Threshold
  fields as AC_DRC0_HOPL
0x768 AC_DRC1_LOPL reset 0xFBA7 — DRC1 Limiter Low Output at Limiter Threshold
  fields as AC_DRC0_HOPL
0x76C AC_DRC1_HET reset 0xBA0 — DRC1 Expander Theshold High Setting Register
  fields as AC_DRC0_HET
0x770 AC_DRC1_LET reset 0x7291 — DRC1 Expander Theshold Low Setting Register
  fields as AC_DRC0_HET
0x774 AC_DRC1_HKE reset 0x50 — DRC1 Expander Slope High Setting Register
  fields as AC_DRC0_HKE
0x778 AC_DRC1_LKE — DRC1 Expander Slope Low Setting Register
  fields as AC_DRC0_LKE
0x77C AC_DRC1_HOPE reset 0xF45F — DRC1 Expander High Output at Expander Threshold
  fields as AC_DRC0_HOPE
0x780 AC_DRC1_LOPE reset 0x8D6E — DRC1 Expander Low Output at Expander Threshold
  fields as AC_DRC0_HOPE
0x784 AC_DRC1_HKN reset 0x100 — DRC1 Linear Slope High Setting Register
  [13:0] LINEAR_SLOPE — The slope of the linear which determine by the equation that Kn = 1/R, there, R is the ratio of the linear, which always is interger. The format is 8.24. (1:1)
0x788 AC_DRC1_LKN — DRC1 Linear Slope Low Setting Register
  [15:0] LINEAR_SLOPE — The slope of the linear which determine by the equation that Kn = 1/R, there, R is the ratio of the linear, which always is interger. The format is 8.24. (1:1)
0x78C AC_DRC1_SFHAT reset 0x2 — DRC1 Smooth filter Gain High Attack Time Coef Register
  fields as AC_DRC0_SFHAT
0x790 AC_DRC1_SFLAT reset 0x5600 — DRC1 Smooth filter Gain Low Attack Time Coef Register
  fields as AC_DRC0_SFLAT
0x794 AC_DRC1_SFHRT — DRC1 Smooth filter Gain High Release Time Coef Register
  fields as AC_DRC0_SFHRT
0x798 AC_DRC1_SFLRT reset 0xF04 — DRC1 Smooth filter Gain Low Release Time Coef Register
  fields as AC_DRC0_SFLRT
0x79C AC_DRC1_MXGHS reset 0xFE56 — DRC1 MAX Gain High Setting Register
  fields as AC_DRC0_MXGHS
0x7A0 AC_DRC1_MXGLS reset 0xCB0F — DRC1 MAX Gain Low Setting Register
  fields as AC_DRC0_MXGLS
0x7A4 AC_DRC1_MNGHS reset 0xF95B — DRC1 MIN Gain High Setting Register
  fields as AC_DRC0_MNGHS
0x7A8 AC_DRC1_MNGLS reset 0x2C3F — DRC1 MIN Gain Low Setting Register
  fields as AC_DRC0_MNGLS
0x7AC AC_DRC1_EPSHC — DRC1 Expander Smooth Time High Coef Register
  fields as AC_DRC0_EPSHC
0x7B0 AC_DRC1_EPSLC reset 0x640C — DRC1 Expander Smooth Time Low Coef Register
  fields as AC_DRC0_EPSLC
0x7B8 AC_DRC1_HPFHGAIN reset 0x100
  fields as AC_DRC0_HPFHGAIN
0x7BC AC_DRC1_HPFLGAIN
  fields as AC_DRC0_HPFLGAIN
